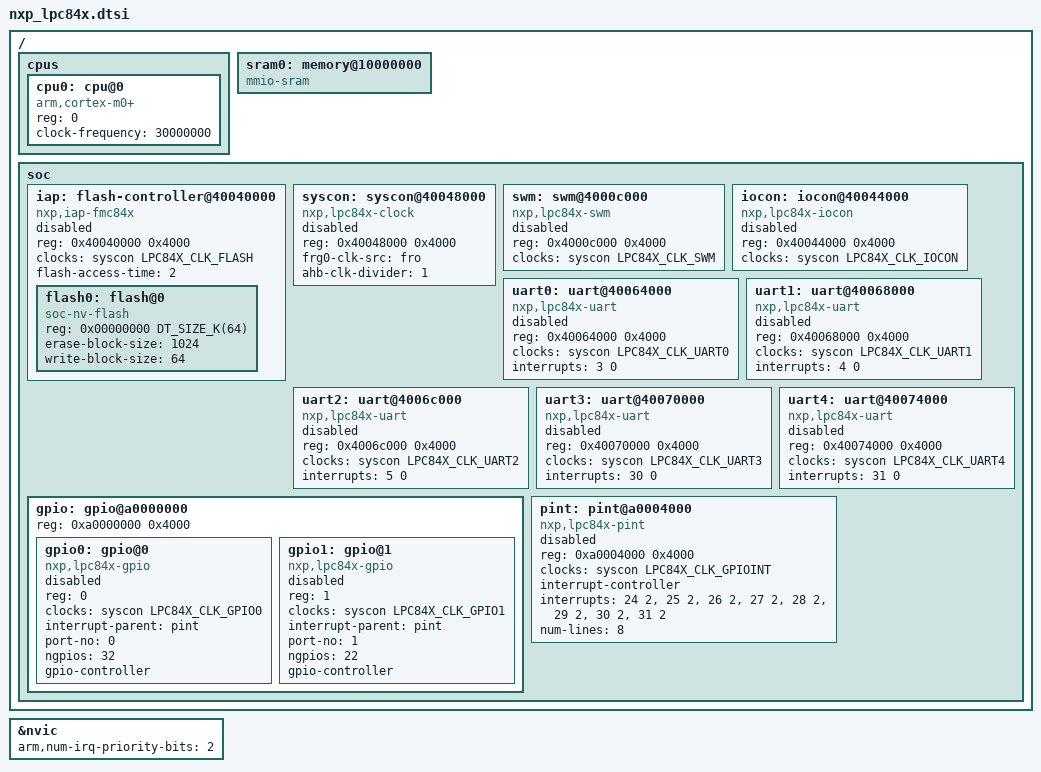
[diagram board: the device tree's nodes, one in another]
/*
 * Copyright (c) 2026 Aerlync Labs Inc.
 *
 * SPDX-License-Identifier: Apache-2.0
 */

#include <arm/armv6-m.dtsi>
#include <mem.h>
#include <zephyr/dt-bindings/clock/lpc84x-clock.h>

/ {
	cpus {
		#address-cells = <1>;
		#size-cells = <0>;

		cpu0: cpu@0 {
			compatible = "arm,cortex-m0+";
			reg = <0>;
			clock-frequency = <30000000>;
		};
	};

	/*
	 * LPC84X have either 8KB or 16KB of SRAM
	 * that should be taken care in board specific .dtsi
	 */
	sram0: memory@10000000 {
		compatible = "mmio-sram";
	};

	soc {
		#address-cells = <1>;
		#size-cells = <1>;
		ranges;

		iap: flash-controller@40040000 {
			compatible = "nxp,iap-fmc84x";
			reg = <0x40040000 0x4000>;
			ranges;
			#address-cells = <1>;
			#size-cells = <1>;
			clocks = <&syscon LPC84X_CLK_FLASH>;
			flash-access-time = <2>;
			status = "disabled";

			flash0: flash@0 {
				compatible = "soc-nv-flash";
				reg = <0x00000000 DT_SIZE_K(64)>;
				ranges = <0x0 0x0 DT_SIZE_K(64)>;
				#address-cells = <1>;
				#size-cells = <1>;
				erase-block-size = <1024>;
				write-block-size = <64>;
			};
		};

		syscon: syscon@40048000 {
			compatible = "nxp,lpc84x-clock";
			reg = <0x40048000 0x4000>;
			#clock-cells = <1>;
			frg0-clk-src = "fro";
			ahb-clk-divider = <1>;
			status = "disabled";
		};

		swm: swm@4000c000 {
			compatible = "nxp,lpc84x-swm";
			reg = <0x4000c000 0x4000>;
			clocks = <&syscon LPC84X_CLK_SWM>;
			status = "disabled";
		};

		iocon: iocon@40044000 {
			compatible = "nxp,lpc84x-iocon";
			reg = <0x40044000 0x4000>;
			clocks = <&syscon LPC84X_CLK_IOCON>;
			status = "disabled";
		};

		uart0: uart@40064000 {
			compatible = "nxp,lpc84x-uart";
			reg = <0x40064000 0x4000>;
			clocks = <&syscon LPC84X_CLK_UART0>;
			interrupts = <3 0>;
			status = "disabled";
		};

		uart1: uart@40068000 {
			compatible = "nxp,lpc84x-uart";
			reg = <0x40068000 0x4000>;
			clocks = <&syscon LPC84X_CLK_UART1>;
			interrupts = <4 0>;
			status = "disabled";
		};

		uart2: uart@4006c000 {
			compatible = "nxp,lpc84x-uart";
			reg = <0x4006c000 0x4000>;
			clocks = <&syscon LPC84X_CLK_UART2>;
			interrupts = <5 0>;
			status = "disabled";
		};

		uart3: uart@40070000 {
			compatible = "nxp,lpc84x-uart";
			reg = <0x40070000 0x4000>;
			clocks = <&syscon LPC84X_CLK_UART3>;
			interrupts = <30 0>;
			status = "disabled";
		};

		uart4: uart@40074000 {
			compatible = "nxp,lpc84x-uart";
			reg = <0x40074000 0x4000>;
			clocks = <&syscon LPC84X_CLK_UART4>;
			interrupts = <31 0>;
			status = "disabled";
		};

		gpio: gpio@a0000000 {
			reg = <0xa0000000 0x4000>;
			#address-cells = <1>;
			#size-cells = <0>;

			gpio0: gpio@0 {
				compatible = "nxp,lpc84x-gpio";
				reg = <0>;
				clocks = <&syscon LPC84X_CLK_GPIO0>;
				interrupt-parent = <&pint>;
				port-no = <0>;
				ngpios = <32>;
				gpio-controller;
				#gpio-cells = <2>;
				status = "disabled";
			};

			gpio1: gpio@1 {
				compatible = "nxp,lpc84x-gpio";
				reg = <1>;
				clocks = <&syscon LPC84X_CLK_GPIO1>;
				interrupt-parent = <&pint>;
				port-no = <1>;
				ngpios = <22>;
				gpio-controller;
				#gpio-cells = <2>;
				status = "disabled";
			};
		};

		pint: pint@a0004000 {
			compatible = "nxp,lpc84x-pint";
			reg = <0xa0004000 0x4000>;
			clocks = <&syscon LPC84X_CLK_GPIOINT>;
			interrupt-controller;
			#interrupt-cells = <1>;
			#address-cells = <0>;
			interrupts = <24 2>, <25 2>, <26 2>, <27 2>,
				     <28 2>, <29 2>, <30 2>, <31 2>;
			num-lines = <8>;
			status = "disabled";
		};
	};
};

&nvic {
	arm,num-irq-priority-bits = <2>;
};
